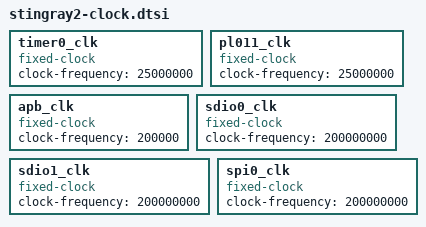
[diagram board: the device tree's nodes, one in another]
// SPDX-License-Identifier: (GPL-2.0 or BSD-3-Clause)
/*
 *  Copyright(c) 2020 Broadcom
 */

timer0_clk: timer0_clk {
	#clock-cells = <0>;
	compatible = "fixed-clock";
	clock-frequency = <25000000>;
};

pl011_clk: pl011_clk {
	#clock-cells = <0>;
	compatible = "fixed-clock";
	clock-frequency = <25000000>;
};

apb_clk: apb_clk {
	#clock-cells = <0>;
	compatible = "fixed-clock";
	clock-frequency = <200000>;
};

sdio0_clk: sdio0_clk {
	#clock-cells = <0>;
	compatible = "fixed-clock";
	clock-frequency = <200000000>;
};

sdio1_clk: sdio1_clk {
	#clock-cells = <0>;
	compatible = "fixed-clock";
	clock-frequency = <200000000>;
};

spi0_clk: spi0_clk {
	#clock-cells = <0>;
	compatible = "fixed-clock";
	clock-frequency = <200000000>;
};
